# STM32L15x register map
File version: 1.0
Registers are 32-bit, read-write, reset 0x0 unless marked. A register's access mark holds for its fields unless they carry their own. Offsets are from the block's base; [hi:lo] are bit positions; {n}, {i} and the like mark numbered series; 'fields as' and 'values as' point back to an identical list.

## USB
Base 0x40005C00
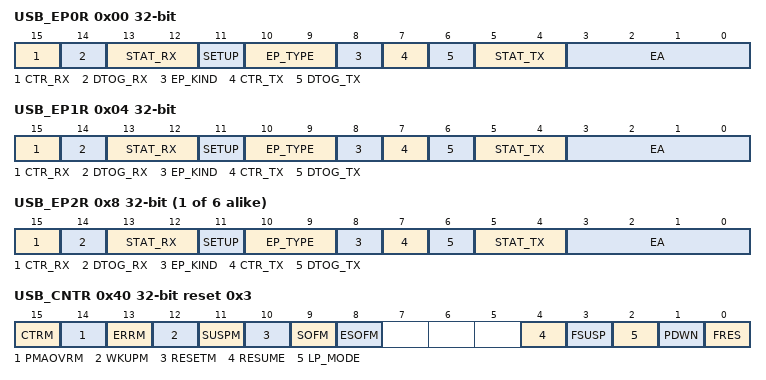
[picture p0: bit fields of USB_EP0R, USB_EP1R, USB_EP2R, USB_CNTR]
0x00 USB_EP0R access per field
  [15] CTR_RX wo, [14] DTOG_RX wo, [13:12] STAT_RX wo, [11] SETUP ro, [10:9] EP_TYPE rw, [8] EP_KIND rw, [7] CTR_TX wo, [6] DTOG_TX wo, [5:4] STAT_TX wo, [3:0] EA rw
0x04 USB_EP1R wo
  [15] CTR_RX, [14] DTOG_RX, [13:12] STAT_RX, [11] SETUP, [10:9] EP_TYPE, [8] EP_KIND, [7] CTR_TX, [6] DTOG_TX, [5:4] STAT_TX, [3:0] EA
{0x0+4i} USB_EP{i}R ro (i=2..7)
  fields as USB_EP1R
0x40 USB_CNTR reset 0x3
  [15] CTRM, [14] PMAOVRM, [13] ERRM, [12] WKUPM, [11] SUSPM, [10] RESETM, [9] SOFM, [8] ESOFM, [4] RESUME, [3] FSUSP, [2] LP_MODE, [1] PDWN, [0] FRES
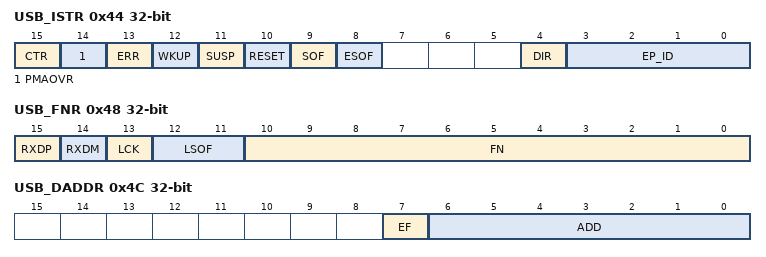
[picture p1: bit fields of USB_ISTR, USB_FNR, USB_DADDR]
0x44 USB_ISTR ro
  [15] CTR, [14] PMAOVR, [13] ERR, [12] WKUP, [11] SUSP, [10] RESET, [9] SOF, [8] ESOF, [4] DIR, [3:0] EP_ID
0x48 USB_FNR ro
  [15] RXDP, [14] RXDM, [13] LCK, [12:11] LSOF, [10:0] FN
0x4C USB_DADDR
  [7] EF, [6:0] ADD
0x50 USB_BTABLE ro
  [15:0] BTABLE

## I2C2 — Inter-integrated circuit
Base 0x40005800
Same registers: I2C1 0x40005400
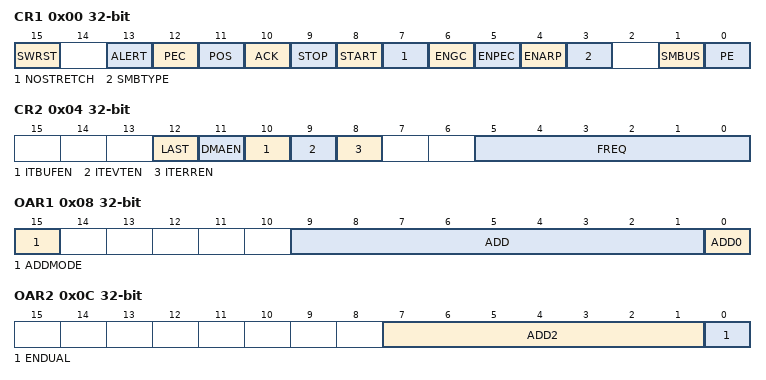
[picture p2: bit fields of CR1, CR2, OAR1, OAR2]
0x00 CR1 — Control register 1
  [15] SWRST, [13] ALERT, [12] PEC, [11] POS, [10] ACK, [9] STOP, [8] START, [7] NOSTRETCH, [6] ENGC, [5] ENPEC, [4] ENARP, [3] SMBTYPE, [1] SMBUS, [0] PE
0x04 CR2 — Control register 2
  [12] LAST, [11] DMAEN, [10] ITBUFEN, [9] ITEVTEN, [8] ITERREN, [5:0] FREQ
0x08 OAR1 — Own address register 1
  [15] ADDMODE, [9:1] ADD, [0] ADD0
0x0C OAR2 — Own address register 2
  [7:1] ADD2, [0] ENDUAL
0x10 DR — Data register
  [7:0] DR
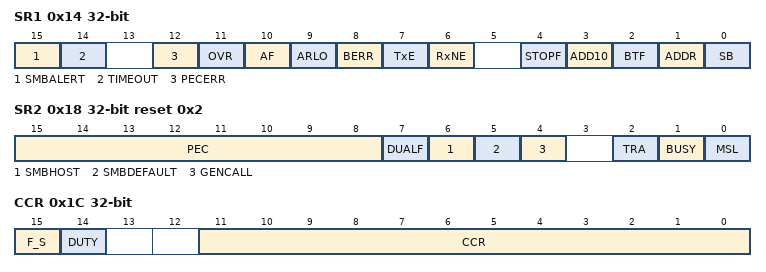
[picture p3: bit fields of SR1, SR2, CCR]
0x14 SR1 ro — Status register 1
  [15] SMBALERT, [14] TIMEOUT, [12] PECERR, [11] OVR, [10] AF, [9] ARLO, [8] BERR, [7] TxE, [6] RxNE, [4] STOPF, [3] ADD10, [2] BTF, [1] ADDR, [0] SB
0x18 SR2 ro reset 0x2 — Status register 2
  [15:8] PEC, [7] DUALF, [6] SMBHOST, [5] SMBDEFAULT, [4] GENCALL, [2] TRA, [1] BUSY, [0] MSL
0x1C CCR — Clock control register
  [15] F_S, [14] DUTY, [11:0] CCR
0x20 TRISE reset 0x2
  [5:0] TRISE

## IWDG — Independent watchdog
Base 0x40003000
0x00 KR ro — Key register
  [15:0] KR
0x04 PR — Prescaler register
  [2:0] PR
0x08 RLR reset 0xFFF — Reload register
  [11:0] RL
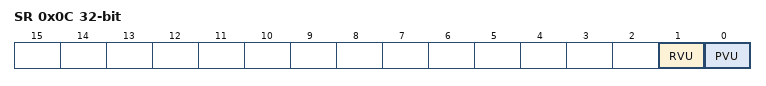
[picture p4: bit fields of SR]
0x0C SR ro — Status register
  [1] RVU, [0] PVU

## WWDG — Window watchdog
Base 0x40002C00
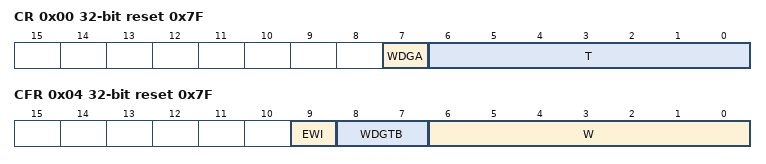
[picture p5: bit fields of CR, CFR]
0x00 CR reset 0x7F — Control register
  [7] WDGA, [6:0] T
0x04 CFR reset 0x7F — Configuration register
  [9] EWI, [8:7] WDGTB, [6:0] W
0x08 SR ro — Status register
  [0] EWIF

## RTC — Real-time clock
Base 0x40002800
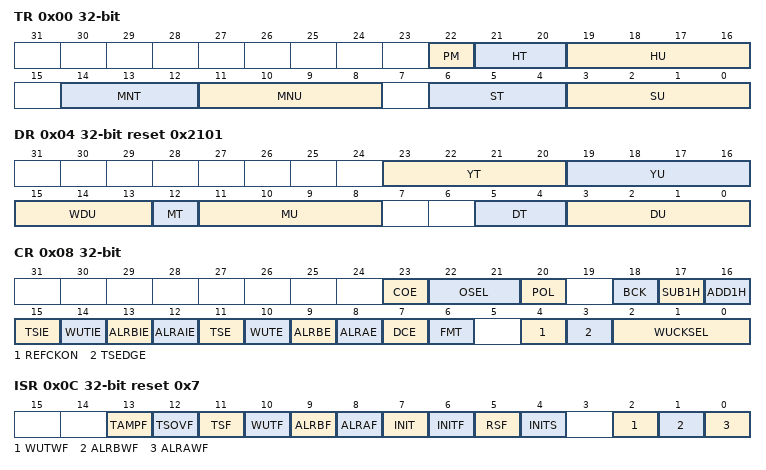
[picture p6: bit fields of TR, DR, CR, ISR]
0x00 TR — RTC time register
  [22] PM, [21:20] HT, [19:16] HU, [14:12] MNT, [11:8] MNU, [6:4] ST, [3:0] SU
0x04 DR reset 0x2101 — RTC date register
  [23:20] YT, [19:16] YU, [15:13] WDU, [12] MT, [11:8] MU, [5:4] DT, [3:0] DU
0x08 CR — RTC control register
  [23] COE, [22:21] OSEL, [20] POL, [18] BCK, [17] SUB1H, [16] ADD1H, [15] TSIE, [14] WUTIE, [13] ALRBIE, [12] ALRAIE, [11] TSE, [10] WUTE, [9] ALRBE, [8] ALRAE, [7] DCE, [6] FMT, [4] REFCKON, [3] TSEDGE, [2:0] WUCKSEL
0x0C ISR access per field reset 0x7 — RTC initialization and status register
  [13] TAMPF ro, [12] TSOVF ro, [11] TSF ro, [10] WUTF ro, [9] ALRBF ro, [8] ALRAF ro, [7] INIT rw, [6] INITF ro, [5] RSF ro, [4] INITS ro, [2] WUTWF ro, [1] ALRBWF ro, [0] ALRAWF ro
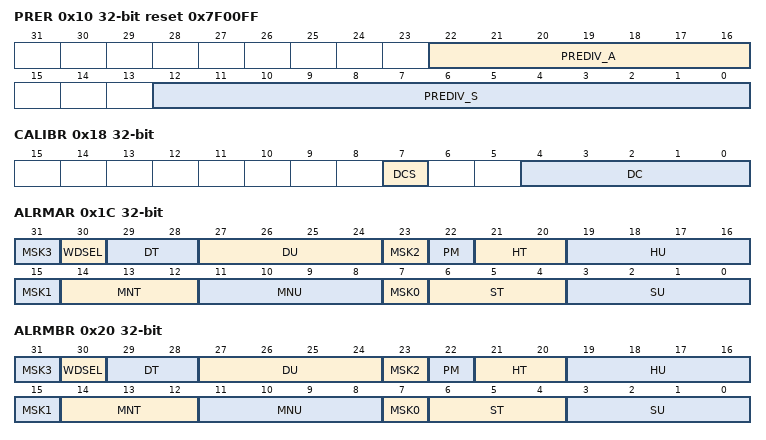
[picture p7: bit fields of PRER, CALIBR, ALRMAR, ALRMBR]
0x10 PRER ro reset 0x7F00FF — RTC prescaler register
  [22:16] PREDIV_A, [12:0] PREDIV_S
0x14 WUTR reset 0xFFFF — RTC wakeup timer register
  [15:0] WUARV
0x18 CALIBR — RTC calibration register
  [7] DCS, [4:0] DC
0x1C ALRMAR — RTC alarm A register
  [8n+7] MSK{n} (n=0..3), [30] WDSEL, [29:28] DT, [27:24] DU, [22] PM, [21:20] HT, [19:16] HU, [14:12] MNT, [11:8] MNU, [6:4] ST, [3:0] SU
0x20 ALRMBR — RTC alarm B register
  fields as ALRMAR
0x24 WPR wo — RTC write protection register
  [7:0] KEY
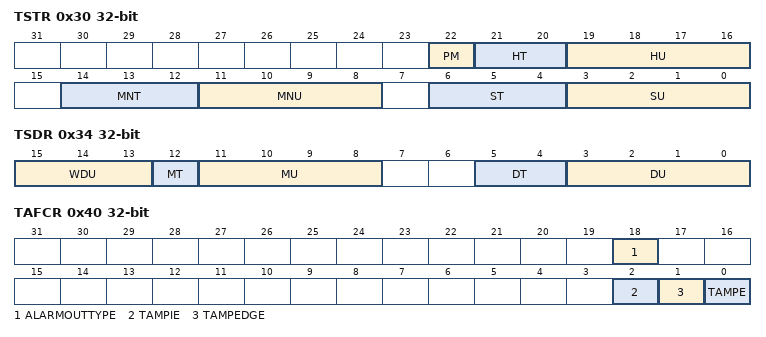
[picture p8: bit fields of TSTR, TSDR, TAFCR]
0x30 TSTR ro — RTC time stamp time register
  fields as TR
0x34 TSDR ro — RTC time stamp date register
  [15:13] WDU, [12] MT, [11:8] MU, [5:4] DT, [3:0] DU
0x40 TAFCR ro — RTC tamper and alternate function configuration register
  [18] ALARMOUTTYPE, [2] TAMPIE, [1] TAMPEDGE, [0] TAMPE
{0x50+4i} BK{i}R (i=0..3) — RTC backup register
0x60 BK4R — RTC backup register
  [31:0] BK4R — BK3R
{0x50+4i} BK{i}R (i=5..19) — RTC backup register
